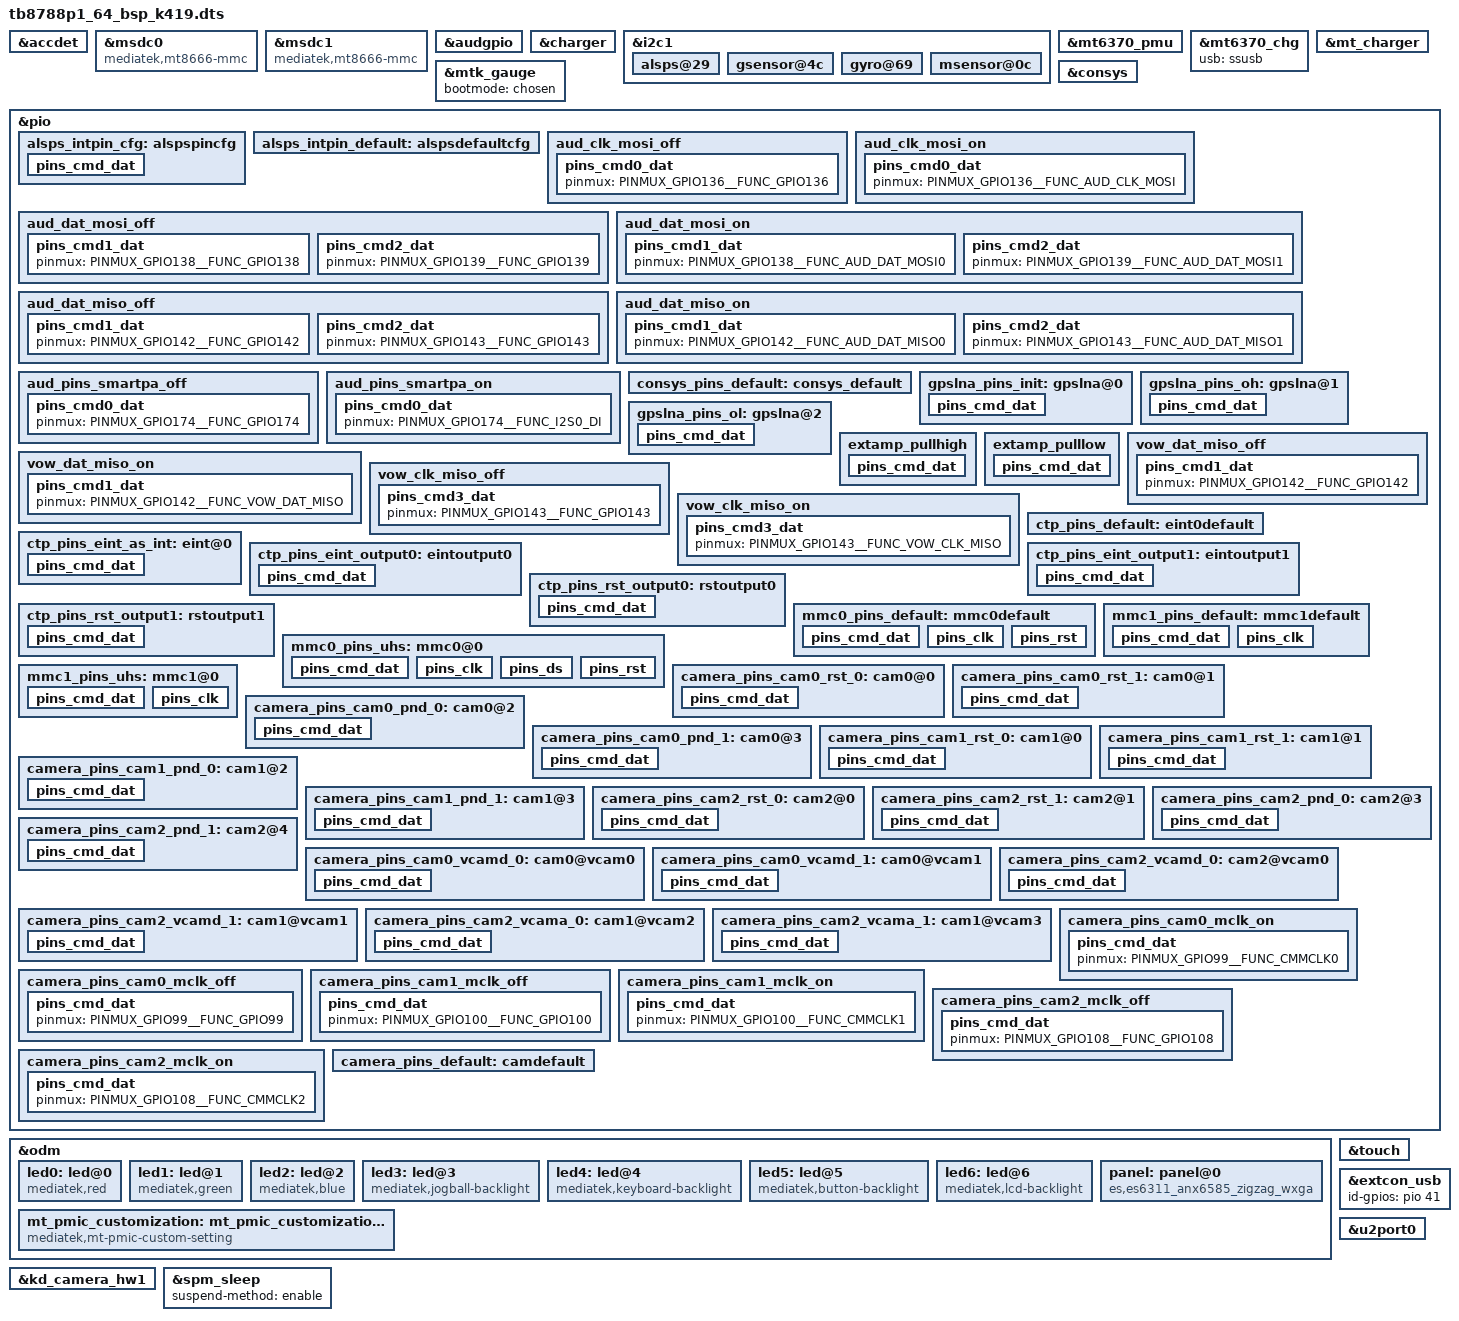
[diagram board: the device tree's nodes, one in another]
// SPDX-License-Identifier: GPL-2.0+
/*
 * Copyright (c) 2019 MediaTek Inc.
 *
 */

#include <dt-bindings/interrupt-controller/arm-gic.h>
#include <dt-bindings/interrupt-controller/irq.h>
#include <dt-bindings/pinctrl/mt6771-pinfunc.h>
#include <dt-bindings/mmc/mt6771-msdc.h>

/dts-v1/;
/plugin/;

/* accdet start */
&accdet {
	/* accdet micbias voltage: 0x07,2.7v;0x05,2.5v;0x02,1.9v */
	accdet-mic-vol = <6>;
	headset-mode-setting = <0x500 0x500 1 0x1f0 0x800 0x800 0x20 0x44>;
	accdet-plugout-debounce = <1>;
	/*1:ACC mode, 2:low cost without in bias, 6:low cost with in bias*/
	accdet-mic-mode = <1>;
	/* eint_level_trigger:
	 *	8,LEVEL_LOW(default);4,LEVEL_HIGH;others,LEVEL_LOW
	 */
	headset-eint-level-pol = <4>;
	/*0--MD_MAX--UP_MAX--DW_MAX*/
	headset-three-key-threshold = <0 80 220 400>;
	headset-three-key-threshold-CDD = <0 121 192 600>;
	/*0--MD_MAX--VOICE_MAX--UP_MAX--DW_MAX*/
	headset-four-key-threshold = <0 58 121 192 400>;
	status = "okay";
};

&msdc0 {
	compatible = "mediatek,mt8666-mmc";
	reg = <0x0 0x11230000 0x0 0x10000>,
	    <0x0 0x11f50000 0x0 0x1000>;
	vmmc-supply = <&mt_pmic_vemc_ldo_reg>;
	vqmmc-supply = <&mt_pmic_vio18_ldo_reg>;
	clock-names = "source", "hclk";
	status = "okay";
	bus-width = <8>;
	max-frequency = <200000000>;
	cap-mmc-highspeed;
	mmc-hs200-1_8v;
	mmc-hs400-1_8v;
	no-sd;
	no-sdio;
	cap-mmc-hw-reset;
	hs400-ds-delay = <0x12814>;
	pinctrl-names = "default", "state_uhs";
	pinctrl-0 = <&mmc0_pins_default>;
	pinctrl-1 = <&mmc0_pins_uhs>;
	non-removable;
};

&msdc1 {
	compatible = "mediatek,mt8666-mmc";
	reg = <0x0 0x11240000 0x0 0x10000>,
	    <0 0x11e10000 0 0x1000>;
	clock-names = "source", "hclk";
	status = "okay";
	bus-width = <4>;
	max-frequency = <200000000>;
	cap-sd-highspeed;
	sd-uhs-sdr50;
	sd-uhs-sdr104;
	no-mmc;
	no-sdio;
	pinctrl-names = "default", "state_uhs";
	pinctrl-0 = <&mmc1_pins_default>;
	pinctrl-1 = <&mmc1_pins_uhs>;
	cd-gpios = <&pio 3 1>;
	vmmc-supply = <&mt_pmic_vmch_ldo_reg>;
	vqmmc-supply = <&mt_pmic_vmc_ldo_reg>;
};

/* AUDIO GPIO standardization */
&audgpio {
	pinctrl-names = "aud_clk_mosi_off",
			"aud_clk_mosi_on",
			"aud_dat_mosi_off",
			"aud_dat_mosi_on",
			"aud_dat_miso_off",
			"aud_dat_miso_on",
			"aud_smartpa_off",
			"aud_smartpa_on",
			"vow_dat_miso_off",
			"vow_dat_miso_on",
			"vow_clk_miso_off",
			"vow_clk_miso_on",
			"extamp-pullhigh",
			"extamp-pulllow";
	pinctrl-0 = <&aud_clk_mosi_off>;
	pinctrl-1 = <&aud_clk_mosi_on>;
	pinctrl-2 = <&aud_dat_mosi_off>;
	pinctrl-3 = <&aud_dat_mosi_on>;
	pinctrl-4 = <&aud_dat_miso_off>;
	pinctrl-5 = <&aud_dat_miso_on>;
	pinctrl-6 = <&aud_pins_smartpa_off>;
	pinctrl-7 = <&aud_pins_smartpa_on>;
	pinctrl-8 = <&vow_dat_miso_off>;
	pinctrl-9 = <&vow_dat_miso_on>;
	pinctrl-10 = <&vow_clk_miso_off>;
	pinctrl-11 = <&vow_clk_miso_on>;
	pinctrl-12 = <&extamp_pullhigh>;
	pinctrl-13 = <&extamp_pulllow>;
	status = "okay";
};

&charger {
	algorithm_name = "DualSwitchCharging";
	chg1_ta_ac_charger_current = <2000000>;
	chg2_ta_ac_charger_current = <2000000>;
	bootmode = <&chosen>;
};

&i2c1 {
	alsps@29 {
		pinctrl-names = "pin_default", "pin_cfg";
		pinctrl-0 = <&alsps_intpin_default>;
		pinctrl-1 = <&alsps_intpin_cfg>;
		status = "okay";
		/* customization */
		i2c_num = <1>;
		i2c_addr = <0x29 0x0 0x0 0x00>;
		polling_mode_ps = <0>;
		polling_mode_als = <1>;
		power_id = <0xffff>;
		power_vol = <0>;
		als_level =
			<0 1 1 7 15 15 100 1000 2000 3000
			6000 10000 14000 18000 20000>;
		als_value =
			<40 40 90 90 160 160 225 320 640 1280
			1280 2600 2600 2600 10240 10240>;
		ps_threshold_high = <900>;
		ps_threshold_low = <600>;
		is_batch_supported_ps = <0>;
		is_batch_supported_als = <0>;
	};

	gsensor@4c {
		i2c_num = <1>;
		i2c_addr = <0x4c 0 0 0>;
		direction = <5>;
		power_id = <0xffff>;
		power_vol = <0>;
		firlen = <16>;
		is_batch_supported = <0>;
	};

	gyro@69 {
		i2c_num = <1>;
		i2c_addr = <0x69 0 0 0>;
		direction = <0>;
		power_id = <0xffff>;
		power_vol = <0>;
		firlen = <16>;
		is_batch_supported = <0>;
	};

	msensor@0c {
		i2c_num = <1>;
		i2c_addr = <0xc 0 0 0>;
		direction = <1>;
		power_id = <0xffff>;
		power_vol = <0>;
		firlen = <16>;
		is_batch_supported = <0>;
	};
};

&mt6370_pmu {
	mt6370,intr_gpio_num = <10>; /* direct defined GPIO num */
	mt6370,intr_gpio = <&pio 10 0x0>;
};

&mt6370_chg {
	usb = <&ssusb>;
};

&mt_charger {
	charger = <&mt6370_pmu>;
	bootmode = <&chosen>;
};

&mtk_gauge {
	bootmode = <&chosen>;
};

&consys {
	pinctrl-names = "default", "gps_lna_state_init",
		"gps_lna_state_oh", "gps_lna_state_ol";
	pinctrl-0 = <&consys_pins_default>;
	pinctrl-1 = <&gpslna_pins_init>;
	pinctrl-2 = <&gpslna_pins_oh>;
	pinctrl-3 = <&gpslna_pins_ol>;
	status = "okay";
};

&pio {
	alsps_intpin_cfg: alspspincfg {
	    pins_cmd_dat {
			pinmux = <PINMUX_GPIO6__FUNC_GPIO6>;
			slew-rate = <0>;
			bias-pull-up = <00>;
		};
	};

	alsps_intpin_default: alspsdefaultcfg {

	};

	aud_clk_mosi_off: aud_clk_mosi_off {
		pins_cmd0_dat {
			pinmux = <PINMUX_GPIO136__FUNC_GPIO136>;
		};
	};

	aud_clk_mosi_on: aud_clk_mosi_on {
		pins_cmd0_dat {
			pinmux = <PINMUX_GPIO136__FUNC_AUD_CLK_MOSI>;
		};
	};

	aud_dat_mosi_off: aud_dat_mosi_off {
		pins_cmd1_dat {
			pinmux = <PINMUX_GPIO138__FUNC_GPIO138>;
		};
		pins_cmd2_dat {
			pinmux = <PINMUX_GPIO139__FUNC_GPIO139>;
		};
	};

	aud_dat_mosi_on: aud_dat_mosi_on {
		pins_cmd1_dat {
			pinmux = <PINMUX_GPIO138__FUNC_AUD_DAT_MOSI0>;
		};
		pins_cmd2_dat {
			pinmux = <PINMUX_GPIO139__FUNC_AUD_DAT_MOSI1>;
		};
	};

	aud_dat_miso_off: aud_dat_miso_off {
		pins_cmd1_dat {
			pinmux = <PINMUX_GPIO142__FUNC_GPIO142>;
		};
		pins_cmd2_dat {
			pinmux = <PINMUX_GPIO143__FUNC_GPIO143>;
		};
	};

	aud_dat_miso_on: aud_dat_miso_on {
		pins_cmd1_dat {
			pinmux = <PINMUX_GPIO142__FUNC_AUD_DAT_MISO0>;
		};
		pins_cmd2_dat {
			pinmux = <PINMUX_GPIO143__FUNC_AUD_DAT_MISO1>;
		};
	};

	aud_pins_smartpa_off: aud_pins_smartpa_off {
		pins_cmd0_dat {
			pinmux = <PINMUX_GPIO174__FUNC_GPIO174>;
		};
	};

	aud_pins_smartpa_on: aud_pins_smartpa_on {
		pins_cmd0_dat {
			pinmux = <PINMUX_GPIO174__FUNC_I2S0_DI>;
		};
	};

	/* CONSYS GPIO standardization */
	consys_pins_default: consys_default {
	};

	gpslna_pins_init: gpslna@0 {
		pins_cmd_dat {
			pinmux = <PINMUX_GPIO155__FUNC_GPIO155>;
			slew-rate = <0>;
			bias-disable;
			output-low;
		};
	};

	gpslna_pins_oh: gpslna@1 {
		pins_cmd_dat {
			pinmux = <PINMUX_GPIO155__FUNC_GPIO155>;
			slew-rate = <1>;
			output-high;
		};
	};

	gpslna_pins_ol: gpslna@2 {
		pins_cmd_dat {
			pinmux = <PINMUX_GPIO155__FUNC_GPIO155>;
			slew-rate = <1>;
			output-low;
		};
	};

	extamp_pullhigh: extamp_pullhigh {
		pins_cmd_dat {
			pinmux = <PINMUX_GPIO0__FUNC_GPIO0>;
			slew-rate = <1>;
			output-high;
		};
	};

	extamp_pulllow: extamp_pulllow {
		pins_cmd_dat {
			pinmux = <PINMUX_GPIO0__FUNC_GPIO0>;
			slew-rate = <1>;
			output-low;
		};
	};

	vow_dat_miso_off: vow_dat_miso_off {
		pins_cmd1_dat {
			pinmux = <PINMUX_GPIO142__FUNC_GPIO142>;
		};
	};

	vow_dat_miso_on: vow_dat_miso_on {
		pins_cmd1_dat {
			pinmux = <PINMUX_GPIO142__FUNC_VOW_DAT_MISO>;
		};
	};

	vow_clk_miso_off: vow_clk_miso_off {
		pins_cmd3_dat {
			pinmux = <PINMUX_GPIO143__FUNC_GPIO143>;
		};
	};

	vow_clk_miso_on: vow_clk_miso_on {
		pins_cmd3_dat {
			pinmux = <PINMUX_GPIO143__FUNC_VOW_CLK_MISO>;
		};
	};
	/* AUDIO end */

	ctp_pins_default: eint0default {
	};

	ctp_pins_eint_as_int: eint@0 {
		pins_cmd_dat {
			pinmux = <PINMUX_GPIO1__FUNC_GPIO1>;
			slew-rate = <0>;
			bias-disable;
		};
	};

	ctp_pins_eint_output0: eintoutput0 {
		pins_cmd_dat {
			pinmux = <PINMUX_GPIO1__FUNC_GPIO1>;
			slew-rate = <1>;
			output-low;
		};
	};

	ctp_pins_eint_output1: eintoutput1 {
		pins_cmd_dat {
			pinmux = <PINMUX_GPIO1__FUNC_GPIO1>;
			slew-rate = <1>;
			output-high;
		};
	};

	ctp_pins_rst_output0: rstoutput0 {
		pins_cmd_dat {
			pinmux = <PINMUX_GPIO2__FUNC_GPIO2>;
			slew-rate = <1>;
			output-low;
		};
	};

	ctp_pins_rst_output1: rstoutput1 {
		pins_cmd_dat {
			pinmux = <PINMUX_GPIO2__FUNC_GPIO2>;
			slew-rate = <1>;
			output-high;
		};
	};

	mmc0_pins_default: mmc0default {
		pins_cmd_dat {
			pinmux = <PINMUX_GPIO123__FUNC_MSDC0_DAT0>,
				<PINMUX_GPIO128__FUNC_MSDC0_DAT1>,
				<PINMUX_GPIO125__FUNC_MSDC0_DAT2>,
				<PINMUX_GPIO132__FUNC_MSDC0_DAT3>,
				<PINMUX_GPIO126__FUNC_MSDC0_DAT4>,
				<PINMUX_GPIO129__FUNC_MSDC0_DAT5>,
				<PINMUX_GPIO127__FUNC_MSDC0_DAT6>,
				<PINMUX_GPIO130__FUNC_MSDC0_DAT7>,
				<PINMUX_GPIO122__FUNC_MSDC0_CMD>;
			input-enable;
			bias-pull-up = <MTK_PUPD_SET_R1R0_01>;
		};

		pins_clk {
			pinmux = <PINMUX_GPIO124__FUNC_MSDC0_CLK>;
			drive-strength = <4>;
			bias-pull-down = <MTK_PUPD_SET_R1R0_10>;
		};

		pins_rst {
			pinmux = <PINMUX_GPIO133__FUNC_MSDC0_RSTB>;
			drive-strength = <4>;
			bias-pull-up = <MTK_PUPD_SET_R1R0_10>;
		};
	};

	mmc0_pins_uhs: mmc0@0{
		pins_cmd_dat {
			pinmux = <PINMUX_GPIO123__FUNC_MSDC0_DAT0>,
				<PINMUX_GPIO128__FUNC_MSDC0_DAT1>,
				<PINMUX_GPIO125__FUNC_MSDC0_DAT2>,
				<PINMUX_GPIO132__FUNC_MSDC0_DAT3>,
				<PINMUX_GPIO126__FUNC_MSDC0_DAT4>,
				<PINMUX_GPIO129__FUNC_MSDC0_DAT5>,
				<PINMUX_GPIO127__FUNC_MSDC0_DAT6>,
				<PINMUX_GPIO130__FUNC_MSDC0_DAT7>,
				<PINMUX_GPIO122__FUNC_MSDC0_CMD>;
			input-enable;
			drive-strength = <4>;
			bias-pull-up = <MTK_PUPD_SET_R1R0_01>;
		};

		pins_clk {
			pinmux = <PINMUX_GPIO124__FUNC_MSDC0_CLK>;
			drive-strength = <4>;
			bias-pull-down = <MTK_PUPD_SET_R1R0_10>;
		};

		pins_ds {
			pinmux = <PINMUX_GPIO131__FUNC_MSDC0_DSL>;
			drive-strength = <4>;
			bias-pull-down = <MTK_PUPD_SET_R1R0_10>;
		};

		pins_rst {
			pinmux = <PINMUX_GPIO133__FUNC_MSDC0_RSTB>;
			drive-strength = <4>;
			bias-pull-up = <MTK_PUPD_SET_R1R0_10>;
		};
	};

	mmc1_pins_default: mmc1default {
		pins_cmd_dat {
			pinmux = <PINMUX_GPIO32__FUNC_MSDC1_DAT0>,
			       <PINMUX_GPIO34__FUNC_MSDC1_DAT1>,
			       <PINMUX_GPIO33__FUNC_MSDC1_DAT2>,
			       <PINMUX_GPIO30__FUNC_MSDC1_DAT3>,
			       <PINMUX_GPIO31__FUNC_MSDC1_CMD>;
			input-enable;
			drive-strength = /bits/ 8 <3>;
			bias-pull-up = <MTK_PUPD_SET_R1R0_01>;
		};

		pins_clk {
			pinmux = <PINMUX_GPIO29__FUNC_MSDC1_CLK>;
			drive-strength = <3>;
			bias-pull-down = <MTK_PUPD_SET_R1R0_10>;
		};
	};

	mmc1_pins_uhs: mmc1@0 {
		pins_cmd_dat {
			pinmux = <PINMUX_GPIO32__FUNC_MSDC1_DAT0>,
			       <PINMUX_GPIO34__FUNC_MSDC1_DAT1>,
			       <PINMUX_GPIO33__FUNC_MSDC1_DAT2>,
			       <PINMUX_GPIO30__FUNC_MSDC1_DAT3>,
			       <PINMUX_GPIO31__FUNC_MSDC1_CMD>;
			input-enable;
			drive-strength = <3>;
			bias-pull-up = <MTK_PUPD_SET_R1R0_01>;
		};

		pins_clk {
			pinmux = <PINMUX_GPIO29__FUNC_MSDC1_CLK>;
			drive-strength = <3>;
			bias-pull-down = <MTK_PUPD_SET_R1R0_10>;
		};
	};
};

&odm {
	led0:led@0 {
		compatible = "mediatek,red";
		led_mode = <0>;
		data = <1>;
		pwm_config = <0 0 0 0 0>;
	};

	led1:led@1 {
		compatible = "mediatek,green";
		led_mode = <0>;
		data = <1>;
		pwm_config = <0 0 0 0 0>;
	};

	led2:led@2 {
		compatible = "mediatek,blue";
		led_mode = <0>;
		data = <1>;
		pwm_config = <0 0 0 0 0>;
	};

	led3:led@3 {
		compatible = "mediatek,jogball-backlight";
		led_mode = <0>;
		data = <1>;
		pwm_config = <0 0 0 0 0>;
	};

	led4:led@4 {
		compatible = "mediatek,keyboard-backlight";
		led_mode = <0>;
		data = <1>;
		pwm_config = <0 0 0 0 0>;
	};

	led5:led@5 {
		compatible = "mediatek,button-backlight";
		led_mode = <0>;
		data = <1>;
		pwm_config = <0 0 0 0 0>;
	};

	led6:led@6 {
		compatible = "mediatek,lcd-backlight";
		led_mode = <5>;
		data = <1>;
		pwm_config = <0 1 0 0 0>;
	};

	panel: panel@0 {
		compatible = "es,es6311_anx6585_zigzag_wxga";
		gpio_lcd_pwr_en = <&pio 158 0>;
		lcd_rst_pin = <&pio 45 0>;
		status = "okay";
	};

	mt_pmic_customization: mt_pmic_customization@0 {
		compatible = "mediatek,mt-pmic-custom-setting";
		custom-reg = <0x1c32 0x1 0x7 0x0 /* LDO_VRF12_OP_EN */
			      0x18ba 0x1 0x1 0x0 /* RG_VPA_NDIS_EN */
		>;
		disable-modem = <1>;
	};
};

&touch {
	tpd-resolution = <800 1280>;
	use-tpd-button = <0>;
	tpd-key-num = <3>;
	tpd-key-local= <139 172 158 0>;
	tpd-key-dim-local =
		<90 883 100 40 230 883 100 40 370 883 100 40 0 0 0 0>;
	tpd-max-touch-num = <5>;
	tpd-filter-enable = <1>;
	tpd-filter-pixel-density = <146>;
	tpd-filter-custom-prameters = <0 0 0 0 0 0 0 0 0 0 0 0>;
	tpd-filter-custom-speed = <0 0 0>;
	pinctrl-names = "default", "state_eint_as_int", "state_eint_output0",
		"state_eint_output1", "state_rst_output0", "state_rst_output1";
	pinctrl-0 = <&ctp_pins_default>;
	pinctrl-1 = <&ctp_pins_eint_as_int>;
	pinctrl-2 = <&ctp_pins_eint_output0>;
	pinctrl-3 = <&ctp_pins_eint_output1>;
	pinctrl-4 = <&ctp_pins_rst_output0>;
	pinctrl-5 = <&ctp_pins_rst_output1>;
	status = "okay";
};

&kd_camera_hw1 {
	pinctrl-names = "default",
			"cam0_rst0", "cam0_rst1",
			"cam0_pnd0", "cam0_pnd1",
			"cam1_rst0", "cam1_rst1",
			"cam1_pnd0", "cam1_pnd1",
			"cam2_rst0", "cam2_rst1",
			"cam2_pnd0", "cam2_pnd1",
			"cam_ldo_vcamd_0", "cam_ldo_vcamd_1",
			"cam_ldo_main2_vcamd_0", "cam_ldo_main2_vcamd_1",
			"cam_ldo_main2_vcama_0", "cam_ldo_main2_vcama_1",
			"cam0_mclk_off", "cam0_mclk_on",
			"cam1_mclk_off", "cam1_mclk_on",
			"cam2_mclk_off", "cam2_mclk_on";
	pinctrl-0 = <&camera_pins_default>;
	pinctrl-1 = <&camera_pins_cam0_rst_0>;
	pinctrl-2 = <&camera_pins_cam0_rst_1>;
	pinctrl-3 = <&camera_pins_cam0_pnd_0>;
	pinctrl-4 = <&camera_pins_cam0_pnd_1>;
	pinctrl-5 = <&camera_pins_cam1_rst_0>;
	pinctrl-6 = <&camera_pins_cam1_rst_1>;
	pinctrl-7 = <&camera_pins_cam1_pnd_0>;
	pinctrl-8 = <&camera_pins_cam1_pnd_1>;
	pinctrl-9 = <&camera_pins_cam2_rst_0>;
	pinctrl-10 = <&camera_pins_cam2_rst_1>;
	pinctrl-11 = <&camera_pins_cam2_pnd_0>;
	pinctrl-12 = <&camera_pins_cam2_pnd_1>;
	pinctrl-13 = <&camera_pins_cam0_vcamd_0>;
	pinctrl-14 = <&camera_pins_cam0_vcamd_1>;
	pinctrl-15 = <&camera_pins_cam2_vcamd_0>;
	pinctrl-16 = <&camera_pins_cam2_vcamd_1>;
	pinctrl-17 = <&camera_pins_cam2_vcama_0>;
	pinctrl-18 = <&camera_pins_cam2_vcama_1>;
	pinctrl-19 = <&camera_pins_cam0_mclk_off>;
	pinctrl-20 = <&camera_pins_cam0_mclk_on>;
	pinctrl-21 = <&camera_pins_cam1_mclk_off>;
	pinctrl-22 = <&camera_pins_cam1_mclk_on>;
	pinctrl-23 = <&camera_pins_cam2_mclk_off>;
	pinctrl-24 = <&camera_pins_cam2_mclk_on>;

	status = "okay";
};

&pio {
	/* CAMERA GPIO standardization */
	camera_pins_cam0_rst_0: cam0@0 {
		pins_cmd_dat {
			pinmux = <PINMUX_GPIO101__FUNC_GPIO101>;
			/*direction 0:in, 1:out*/
			slew-rate = <1>;
			/*direction out used only. output_low or high*/
			output-low;
		};
	};

	camera_pins_cam0_rst_1: cam0@1 {
		pins_cmd_dat {
			pinmux = <PINMUX_GPIO101__FUNC_GPIO101>;
			slew-rate = <1>;
			output-high;
		};
	};

	camera_pins_cam0_pnd_0: cam0@2 {
		pins_cmd_dat {
			pinmux = <PINMUX_GPIO97__FUNC_GPIO97>;
			slew-rate = <1>;
			output-low;
		};
	};

	camera_pins_cam0_pnd_1: cam0@3 {
		pins_cmd_dat {
			pinmux = <PINMUX_GPIO97__FUNC_GPIO97>;
			slew-rate = <1>;
			output-high;
		};
	};

	camera_pins_cam1_rst_0: cam1@0 {
		pins_cmd_dat {
			pinmux = <PINMUX_GPIO102__FUNC_GPIO102>;
			/*direction 0:in, 1:out*/
			slew-rate = <1>;
			/*direction out used only. output_low or high*/
			output-low;
		};
	};

	camera_pins_cam1_rst_1: cam1@1 {
		pins_cmd_dat {
			pinmux = <PINMUX_GPIO102__FUNC_GPIO102>;
			slew-rate = <1>;
			output-high;
		};
	};

	camera_pins_cam1_pnd_0: cam1@2 {
		pins_cmd_dat {
			pinmux = <PINMUX_GPIO98__FUNC_GPIO98>;
			slew-rate = <1>;
			output-low;
		};
	};

	camera_pins_cam1_pnd_1: cam1@3 {
		pins_cmd_dat {
			pinmux = <PINMUX_GPIO98__FUNC_GPIO98>;
			slew-rate = <1>;
			output-high;
		};
	};

	camera_pins_cam2_rst_0: cam2@0 {
		pins_cmd_dat {
			pinmux = <PINMUX_GPIO109__FUNC_GPIO109>;
			slew-rate = <1>;
			output-low;
		};
	};

	camera_pins_cam2_rst_1: cam2@1 {
		pins_cmd_dat {
			pinmux = <PINMUX_GPIO109__FUNC_GPIO109>;
			slew-rate = <1>;
			output-high;
		};
	};

	camera_pins_cam2_pnd_0: cam2@3 {
		pins_cmd_dat {
			pinmux = <PINMUX_GPIO107__FUNC_GPIO107>;
			slew-rate = <1>;
			output-low;
		};
	};

	camera_pins_cam2_pnd_1: cam2@4 {
		pins_cmd_dat {
			pinmux = <PINMUX_GPIO107__FUNC_GPIO107>;
			slew-rate = <1>;
			output-high;
		};
	};

	camera_pins_cam0_vcamd_0: cam0@vcam0 {
		pins_cmd_dat {
			pinmux = <PINMUX_GPIO91__FUNC_GPIO91>;
			slew-rate = <1>;
			output-low;
		};
	};

	camera_pins_cam0_vcamd_1: cam0@vcam1 {
		pins_cmd_dat {
			pinmux = <PINMUX_GPIO91__FUNC_GPIO91>;
			slew-rate = <1>;
			output-high;
		};
	};

	camera_pins_cam2_vcamd_0: cam2@vcam0 {
		pins_cmd_dat {
			pinmux = <PINMUX_GPIO169__FUNC_GPIO169>;
			slew-rate = <1>;
			output-low;
		};
	};

	camera_pins_cam2_vcamd_1: cam1@vcam1 {
		pins_cmd_dat {
			pinmux = <PINMUX_GPIO169__FUNC_GPIO169>;
			slew-rate = <1>;
			output-high;
		};
	};

	camera_pins_cam2_vcama_0: cam1@vcam2 {
		pins_cmd_dat {
			pinmux = <PINMUX_GPIO169__FUNC_GPIO169>;
			slew-rate = <1>;
			output-low;
		};
	};

	camera_pins_cam2_vcama_1: cam1@vcam3 {
		pins_cmd_dat {
			pinmux = <PINMUX_GPIO169__FUNC_GPIO169>;
			slew-rate = <1>;
			output-high;
		};
	};

	camera_pins_cam0_mclk_on: camera_pins_cam0_mclk_on {
		pins_cmd_dat {
			pinmux = <PINMUX_GPIO99__FUNC_CMMCLK0>;
		};
	};

	camera_pins_cam0_mclk_off: camera_pins_cam0_mclk_off {
		pins_cmd_dat {
			pinmux = <PINMUX_GPIO99__FUNC_GPIO99>;
		};
	};

	camera_pins_cam1_mclk_off: camera_pins_cam1_mclk_off {
		pins_cmd_dat {
			pinmux = <PINMUX_GPIO100__FUNC_GPIO100>;
		};
	};

	camera_pins_cam1_mclk_on: camera_pins_cam1_mclk_on {
		pins_cmd_dat {
			pinmux = <PINMUX_GPIO100__FUNC_CMMCLK1>;
		};
	};

	camera_pins_cam2_mclk_off: camera_pins_cam2_mclk_off {
		pins_cmd_dat {
			pinmux = <PINMUX_GPIO108__FUNC_GPIO108>;
		};
	};

	camera_pins_cam2_mclk_on: camera_pins_cam2_mclk_on {
		pins_cmd_dat {
			pinmux = <PINMUX_GPIO108__FUNC_CMMCLK2>;
		};
	};

	camera_pins_default: camdefault {
	};
};

&spm_sleep {
	suspend-method = "enable";
};

&extcon_usb {
	id-gpios = <&pio 41 0x0>;
	status = "okay";
};

&u2port0 {
	mediatek,eye-src = <5>; /* 0~7 */
	mediatek,eye-vrt = <6>; /* 0~7 */
	mediatek,eye-term = <6>; /* 0~7 */
	mediatek,eye-rev6 = <1>; /* 0~3 */
	mediatek,eye-disc = <15>; /* 0~15 */
	mediatek,host-eye-src = <5>; /* 0~7 */
	mediatek,host-eye-vrt = <6>; /* 0~7 */
	mediatek,host-eye-term = <6>; /* 0~7 */
	mediatek,host-eye-rev6 = <1>; /* 0~3 */
	mediatek,host-eye-disc = <15>; /* 0~15 */
};

#include <tb8788p1_64_bsp_k419/cust.dtsi>

/*End of this file, DO NOT ADD ANYTHING HERE*/
